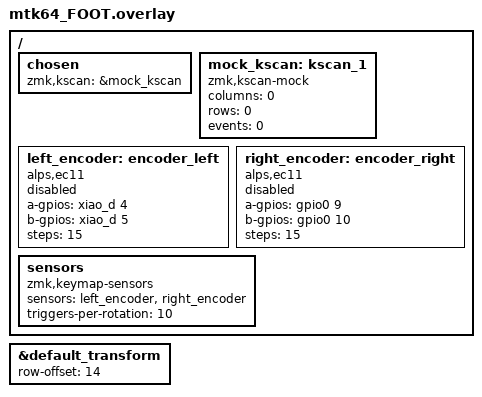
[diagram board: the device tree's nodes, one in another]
#include "mtk64.dtsi"
//#include "mtk64_trackball.dtsi"

&default_transform {
    row-offset = <14>;
};
/*
&trackball_listener {
    status = "okay";  
};
*/
/ {
   chosen {
      zmk,kscan = &mock_kscan;
   };

   mock_kscan: kscan_1 {
      compatible = "zmk,kscan-mock";
      columns = <0>;
      rows = <0>;
      events = <0>;
   };

    left_encoder: encoder_left {
        compatible = "alps,ec11";
        a-gpios = <&xiao_d 4 (GPIO_ACTIVE_HIGH | GPIO_PULL_UP)>;
        b-gpios = <&xiao_d 5 (GPIO_ACTIVE_HIGH | GPIO_PULL_UP)>;
        steps = <15>;
        status = "disabled";
    };

    right_encoder: encoder_right {
        compatible = "alps,ec11";
        a-gpios = <&gpio0 9 (GPIO_ACTIVE_HIGH | GPIO_PULL_UP)>;
        b-gpios = <&gpio0 10 (GPIO_ACTIVE_HIGH | GPIO_PULL_UP)>;
        steps = <15>;
        status = "disabled";
    };

    sensors: sensors {
        compatible = "zmk,keymap-sensors";
        sensors = <&left_encoder &right_encoder>;
        triggers-per-rotation = <10>;
    };
};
